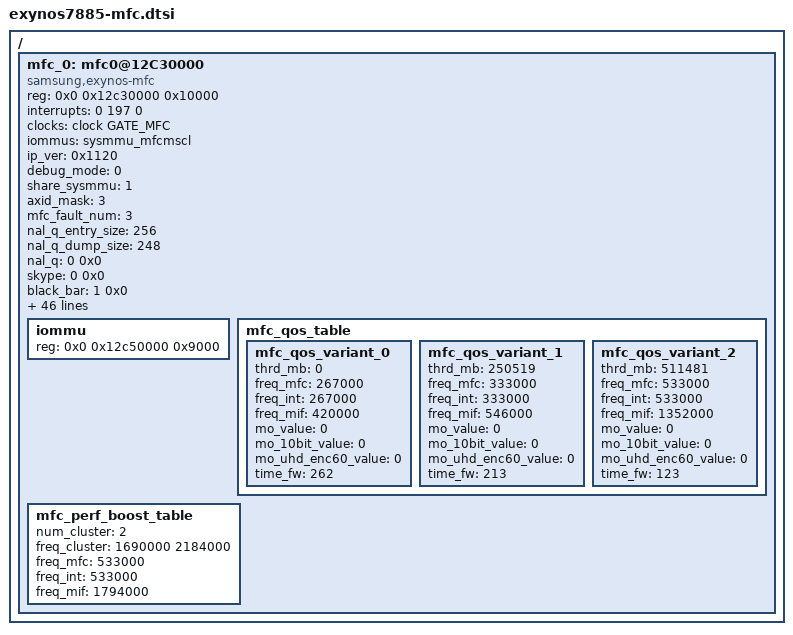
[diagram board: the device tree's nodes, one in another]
/*
 * SAMSUNG EXYNOS SoC mfc device tree source
 *
 * Copyright (c) 2018 Samsung Electronics Co., Ltd.
 *		http://www.samsung.com
 *
 * SAMSUNG EXYNOS SoC mfc device nodes are listed in this file.
 * EXYNOS based board files can include this file and provide
 * values for board specfic bindings.
 *
 * This program is free software; you can redistribute it and/or modify
 * it under the terms of the GNU General Public License version 2 as
 * published by the Free Software Foundation.
 */

#include <dt-bindings/clock/exynos7885.h>
#include <dt-bindings/interrupt-controller/arm-gic.h>

/ {
	mfc_0: mfc0@12C30000 {
		/* Basic setting */
		compatible = "samsung,exynos-mfc";
		reg = <0x0 0x12c30000 0x10000>;
		interrupts = <0 197 0>;
		clock-names = "aclk_mfc";
		clocks = <&clock GATE_MFC>;
		iommus = <&sysmmu_mfcmscl>;

		/* MFC version */
		ip_ver = <0x1120>;

		/* Debug mode */
		debug_mode = <0>;

		/* Sysmmu check */
		share_sysmmu = <1>;
		axid_mask = <3>;
		mfc_fault_num = <3>;

		/* NAL-Q size */
		nal_q_entry_size = <256>;
		nal_q_dump_size = <248>;

		/* Features <on/off version> */
		nal_q = <0 0x0>;
		skype = <0 0x0>;
		black_bar = <1 0x0>;
		color_aspect_dec = <1 0x0>;
		static_info_dec = <1 0x0>;
		color_aspect_enc = <1 0x0>;
		static_info_enc = <0 0>;
		hdr10_plus = <0 0x0>;

		/* Default 10bit format for decoding (1: P010, 0: 8+2) */
		P010_decoding = <0>;

		/* Formats */
		support_10bit = <0>;
		support_422 = <0>;
		support_rgb = <0>;

		/* HDR10+ num max window */
		max_hdr_win = <0>;

		/* Encoder default parameter: max number is 100 */
		enc_param_num = <48>;
		enc_param_addr = <0xf784 0xf794 0xf7b4 0xf7b8 0xfa08 0xf7b0
				0xfa0c 0xfa5c 0xfa10 0xfbac 0xf798 0xf79c
				0xf7a0 0xf7a4 0xfa20 0xfa24 0xfa2c 0xf78c
				0xf790 0xfa34 0xfa38 0xfa3c 0xfdd4 0xfdd8
				0xfddc 0xfde0 0xfde4 0xfb54 0xfb58 0xfb5c
				0xfb60 0xfb64 0xfba8 0xfdb0 0xfdb8 0xfd90
				0xfd98 0xfd40 0xfd48 0xfd4c 0xfd50 0xfd80
				0xfa1c 0xfa00 0xfa04 0xfa30 0xfa40 0xfa44>;
		enc_param_val = <0x0 0x0 0x80 0x80 0x0 0x0 
				0x1e 0x0 0x0 0x8 0x4000 0x0 0x0 0x2
				0x1e0001 0xf4240 0x3fd00 0x0 0x0 0x0
				0x2710 0x3e8 0x50f215 0x0 0x0 0x0 0x0
				0x3011 0x0 0x0 0x0 0x0 0x0 0x0 0x0
				0x2d 0x3c 0x1d 0xf4240 0x33003300
				0x2 0x1 0x0 0x0 0x0 0x0 0x0 0x0>;

		/* BW <peak, read, write> : KB/UHD frame */
		bw_enc_h264 = <73114 48320 23788>;
		bw_enc_hevc = <61440 39141 21211>;
		bw_enc_hevc_10bit = <0 0 0>;
		bw_enc_vp8 = <73728 48361 24416>;
		bw_enc_vp9 = <0 0 0>;
		bw_enc_vp9_10bit = <0 0 0>;
		bw_enc_mpeg4 = <61440 43664 16794>;
		bw_dec_h264 = <70452 38216 23634>;
		bw_dec_hevc = <63079 31942 20484>;
		bw_dec_hevc_10bit = <0 0 0>;
		bw_dec_vp8 = <50074 26976 22324>;
		bw_dec_vp9 = <50893 26017 19764>;
		bw_dec_vp9_10bit = <0 0 0>;
		bw_dec_mpeg4 = <49972 25368 15770>;

		/* QoS */
		num_qos_steps = <3>;
		max_qos_steps = <3>;
		max_mb = <1511155>;
		mfc_freq_control = <0>;
		mo_control = <1>;
		bw_control = <1>;
		qos_weight_h264_hevc = <100>;
		qos_weight_vp8_vp9 = <25>;
		qos_weight_other_codec = <25>;
		qos_weight_3plane = <80>;
		qos_weight_10bit = <75>;
		qos_weight_422 = <70>;
		qos_weight_bframe = <100>;
		qos_weight_num_of_ref = <100>;
		qos_weight_gpb = <100>;
		qos_weight_num_of_tile = <75>;
		qos_weight_super64_bframe = <60>;

		/* Sub nodes for sysmmu, hwfc and mmcache */
		#address-cells = <0x2>;
		#size-cells = <0x1>;
		ranges;
		iommu {
			reg = <0x0 0x12c50000 0x9000>;
		};

		/* QoS table */
		mfc_qos_table {
			mfc_qos_variant_0 {
				thrd_mb = <0>;
				freq_mfc = <267000>;
				freq_int = <267000>;
				freq_mif = <420000>;
				mo_value = <0>;
				mo_10bit_value = <0>;
				mo_uhd_enc60_value = <0>;
				time_fw = <262>;
			};

			mfc_qos_variant_1 {
				thrd_mb = <250519>;
				freq_mfc = <333000>;
				freq_int = <333000>;
				freq_mif = <546000>;
				mo_value = <0>;
				mo_10bit_value = <0>;
				mo_uhd_enc60_value = <0>;
				time_fw = <213>;
			};

			mfc_qos_variant_2 {
				thrd_mb = <511481>;
				freq_mfc = <533000>;
				freq_int = <533000>;
				freq_mif = <1352000>;
				mo_value = <0>;
				mo_10bit_value = <0>;
				mo_uhd_enc60_value = <0>;
				time_fw = <123>;
			};
		};

		/* QoS table for performance boost mode */
		mfc_perf_boost_table {
			num_cluster = <2>;
			freq_cluster = <1690000 2184000>;
			freq_mfc = <533000>;
			freq_int = <533000>;
			freq_mif = <1794000>;
		};
	};
};
